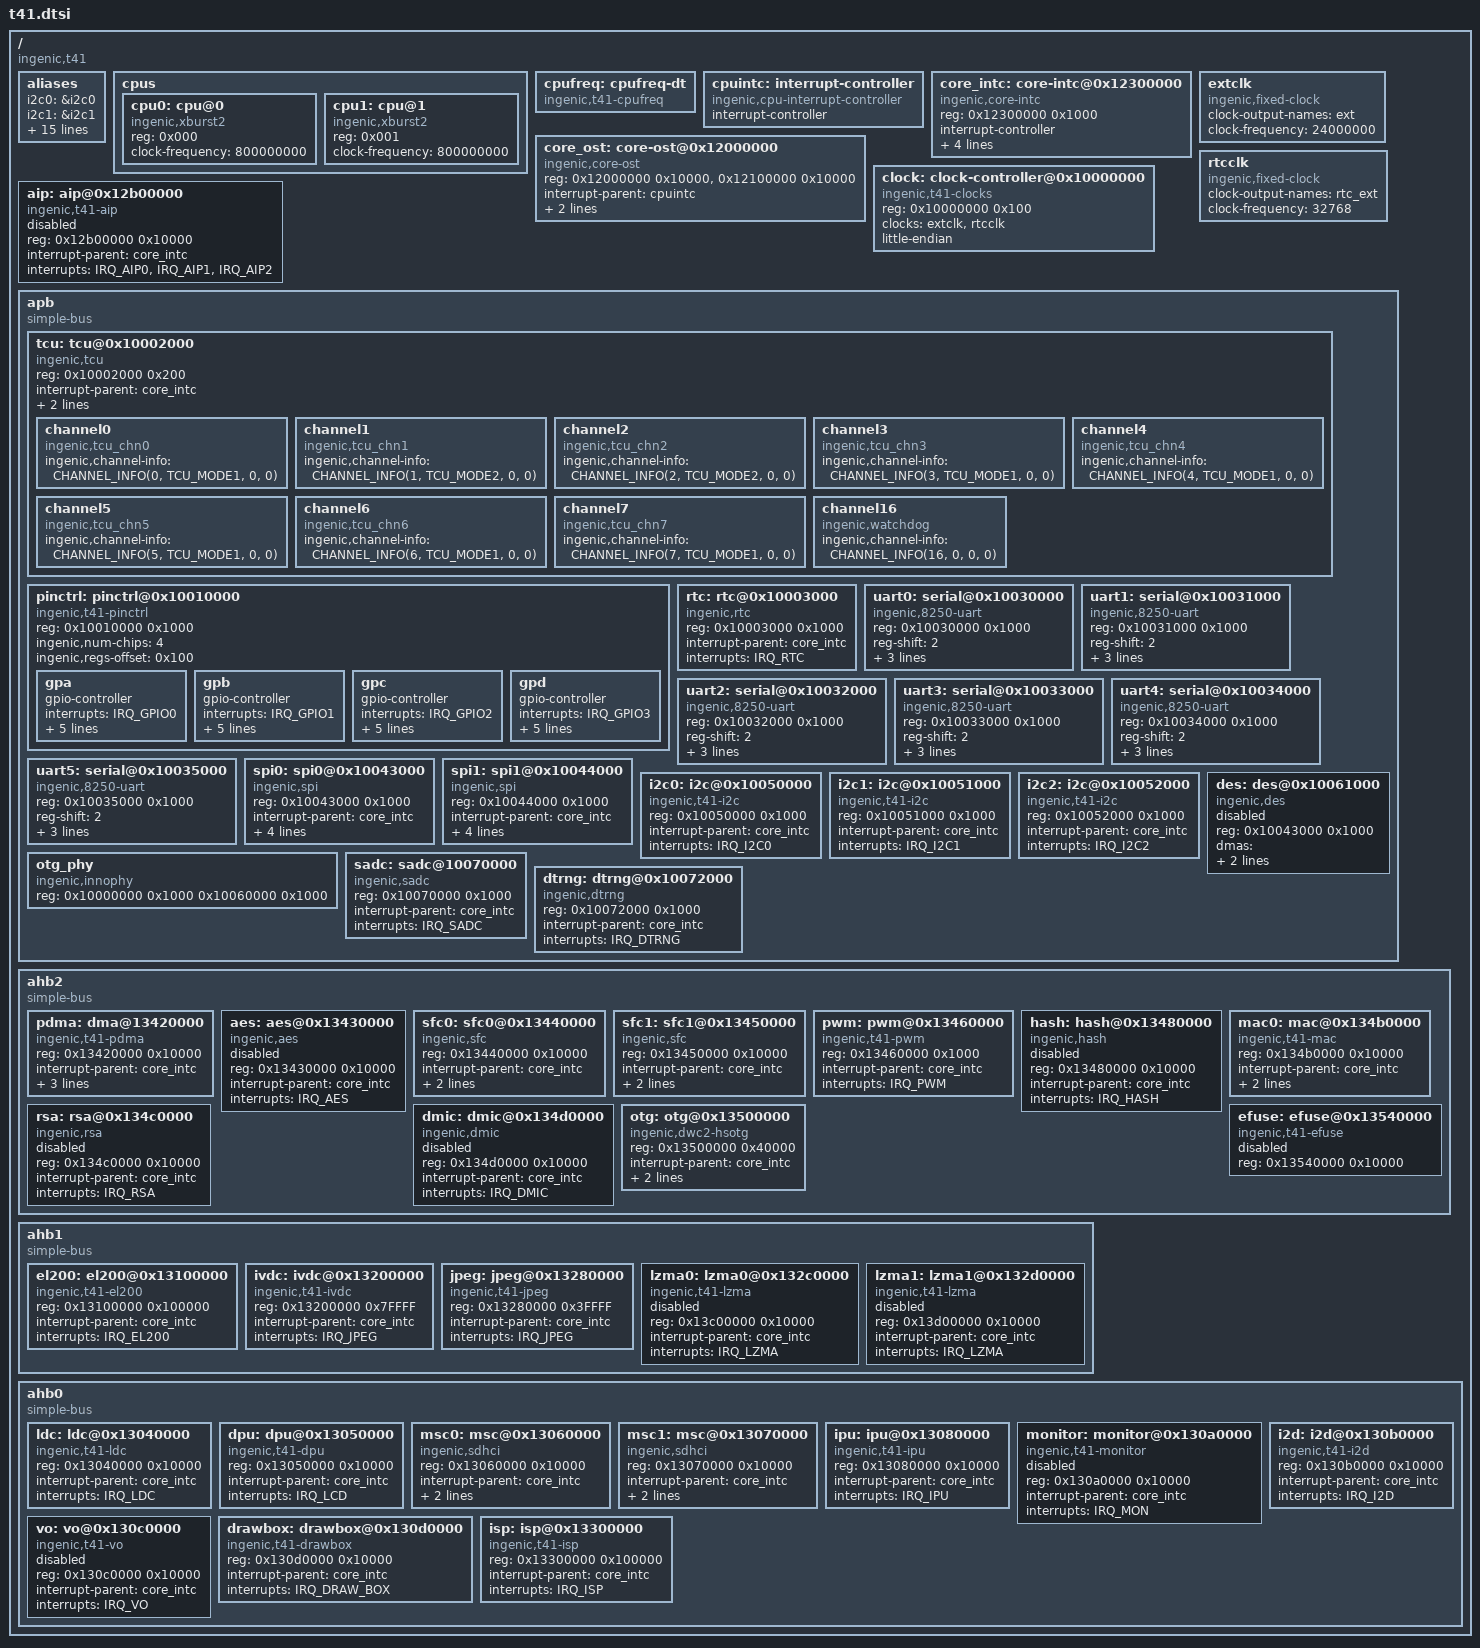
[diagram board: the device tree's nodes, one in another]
#include <dt-bindings/interrupt-controller/t41-irq.h>
#include <dt-bindings/clock/ingenic-tcu.h>
#include <dt-bindings/sound/ingenic-baic.h>
#include <dt-bindings/net/ingenic_gmac.h>
#include <dt-bindings/dma/ingenic-pdma.h>

/ {
	#address-cells = <1>;
	#size-cells = <1>;
	compatible = "ingenic,t41";

	aliases: aliases {
		i2c0 = &i2c0;
		i2c1 = &i2c1;
		i2c2 = &i2c2;
		vo   = &vo;
		uart0 = &uart0;
		uart1 = &uart1;
		uart2 = &uart2;
		uart3 = &uart3;
		uart4 = &uart4;
		uart5 = &uart5;
		msc0 = &msc0;
		msc1 = &msc1;
		mac0 = &mac0;
		spi0 = &spi0;
		spi1 = &spi1;
		sfc0 = &sfc0;
		sfc1 = &sfc1;
	};

	cpus: cpus {
		#address-cells = <1>;
		#size-cells = <0>;

		cpu0: cpu@0 {
			device_type = "cpu";
			compatible = "ingenic,xburst2";
			reg = <0x000>;
			clock-frequency = <800000000>;
		};

		cpu1: cpu@1 {
			device_type = "cpu";
			compatible = "ingenic,xburst2";
			reg = <0x001>;
			clock-frequency = <800000000>;
		};
	};

	cpufreq: cpufreq-dt {
		 compatible = "ingenic,t41-cpufreq";
		 status = "okay";
	};

	cpuintc: interrupt-controller {
		#address-cells = <0>;
		#interrupt-cells = <1>;
		interrupt-controller;
		compatible = "ingenic,cpu-interrupt-controller";

	};

	core_intc: core-intc@0x12300000 {
		compatible = "ingenic,core-intc";
		reg = <0x12300000 0x1000>;
		interrupt-controller;
		#interrupt-cells = <1>;
		cpu-intc-map = <0 0x000>,
				<1 0x100>,
				<2 0x200>,
				<3 0x300>;

		interrupt-parent = <&cpuintc>;
		interrupts = <CORE_INTC_IRQ>;
		interrupt-names ="intc";
	};

	core_ost: core-ost@0x12000000 {
		compatible = "ingenic,core-ost";
		reg = <0x12000000 0x10000>, /*Global ost*/
		      <0x12100000 0x10000>; /*Core ost*/
		interrupt-parent = <&cpuintc>;
		interrupt-names = "sys_ost";
		interrupts = <CORE_SYS_OST_IRQ>;
		cpu-ost-map = 	<0 0x000>,
			<1 0x100>;
	};

	extclk: extclk {
		compatible = "ingenic,fixed-clock";
		clock-output-names ="ext";
		#clock-cells = <0>;
		clock-frequency  = <24000000>;
	};

	rtcclk: rtcclk {
		compatible = "ingenic,fixed-clock";
		clock-output-names ="rtc_ext";
		#clock-cells = <0>;
		clock-frequency = <32768>;
	};

	clock: clock-controller@0x10000000 {
		compatible = "ingenic,t41-clocks";
		reg = <0x10000000 0x100>;
		clocks = <&extclk>, <&rtcclk>;
		clock-names = "ext", "rtc_ext";
		#clock-cells = <1>;
		little-endian;
	};

	aip: aip@0x12b00000 {
		compatible = "ingenic,t41-aip";
		reg = <0x12b00000 0x10000>;
		interrupt-parent = <&core_intc>;
		interrupts = <IRQ_AIP0>,
			<IRQ_AIP1>,
			<IRQ_AIP2>;
		status = "disabled";
	};

	apb {
		compatible = "simple-bus";
		#address-cells = <1>;
		#size-cells = <1>;
		ranges = <>;
		tcu: tcu@0x10002000 {
			compatible = "ingenic,tcu";
			reg = <0x10002000 0x200>;
			interrupt-parent = <&core_intc>;
			interrupt-names = "tcu_int0";
			interrupts = <IRQ_TCU0>;
			interrupt-controller;
			status = "okay";

			channel0: channel0 {
				compatible = "ingenic,tcu_chn0";
				ingenic,channel-info = <CHANNEL_INFO(0, TCU_MODE1, 0, 0)>;
			};
			channel1: channel1 {
				compatible = "ingenic,tcu_chn1";
				ingenic,channel-info = <CHANNEL_INFO(1, TCU_MODE2, 0, 0)>;
			};
			channel2: channel2 {
				compatible = "ingenic,tcu_chn2";
				ingenic,channel-info = <CHANNEL_INFO(2, TCU_MODE2, 0, 0)>;
			};
			channel3: channel3 {
				compatible = "ingenic,tcu_chn3";
				ingenic,channel-info = <CHANNEL_INFO(3, TCU_MODE1, 0, 0)>;
			};
			channel4: channel4 {
				compatible = "ingenic,tcu_chn4";
				ingenic,channel-info = <CHANNEL_INFO(4, TCU_MODE1, 0, 0)>;
			};
			channel5: channel5 {
				compatible = "ingenic,tcu_chn5";
				ingenic,channel-info = <CHANNEL_INFO(5, TCU_MODE1, 0, 0)>;
			};
			channel6: channel6 {
				compatible = "ingenic,tcu_chn6";
				ingenic,channel-info = <CHANNEL_INFO(6, TCU_MODE1, 0, 0)>;
			};
			channel7: channel7 {
				compatible = "ingenic,tcu_chn7";
				ingenic,channel-info = <CHANNEL_INFO(7, TCU_MODE1, 0, 0)>;
			};
			channel16: channel16 {
				compatible = "ingenic,watchdog";
				ingenic,channel-info = <CHANNEL_INFO(16, 0, 0, 0)>;
			};
		};

		pinctrl: pinctrl@0x10010000 {
			compatible = "ingenic,t41-pinctrl";
			reg = <0x10010000 0x1000>;
			ingenic,num-chips = <4>;
			ingenic,regs-offset = <0x100>;

			gpa: gpa {
				gpio-controller;
				#gpio-cells = <3>;
				#ingenic,pincfg-cells = <3>;
				#ingenic,pinmux-cells = <2>;
				interrupts = <IRQ_GPIO0>;
				interrupt-parent = <&core_intc>;
				interrupt-controller;
				#interrupt-cells = <3>;
				ingenic,num-gpios = <32>;
				ingenic,pull-gpios-low = <0x55555555>;
				ingenic,pull-gpios-high = <0x55555555>;
			};

			gpb: gpb {
				gpio-controller;
				#gpio-cells = <3>;
				#ingenic,pincfg-cells = <3>;
				#ingenic,pinmux-cells = <2>;
				interrupts = <IRQ_GPIO1>;
				interrupt-parent = <&core_intc>;
				interrupt-controller;
				#interrupt-cells = <3>;
				ingenic,num-gpios = <32>;
				ingenic,pull-gpios-low = <0x55555555>;
				ingenic,pull-gpios-high = <0x55555555>;
			};

			gpc: gpc {
				gpio-controller;
				#gpio-cells = <3>;
				#ingenic,pincfg-cells = <3>;
				#ingenic,pinmux-cells = <2>;
				interrupts = <IRQ_GPIO2>;
				interrupt-parent = <&core_intc>;
				interrupt-controller;
				#interrupt-cells = <3>;
				ingenic,num-gpios = <32>;
				ingenic,pull-gpios-low = <0x55555555>;
				ingenic,pull-gpios-high = <0x55555555>;
			};

			gpd: gpd {
				gpio-controller;
				#gpio-cells = <3>;
				#ingenic,pincfg-cells = <3>;
				#ingenic,pinmux-cells = <2>;
				interrupts = <IRQ_GPIO3>;
				interrupt-parent = <&core_intc>;
				interrupt-controller;
				#interrupt-cells = <3>;
				ingenic,num-gpios = <32>;
				ingenic,pull-gpios-low = <0x55555555>;
				ingenic,pull-gpios-high = <0x55555555>;
			};
		};

		rtc: rtc@0x10003000 {
			compatible = "ingenic,rtc";
			reg = <0x10003000 0x1000>;
			interrupt-parent = <&core_intc>;
			interrupts = <IRQ_RTC>;
			status = "okay";
		};

		uart0: serial@0x10030000 {
			compatible = "ingenic,8250-uart";
			reg = <0x10030000 0x1000>;
			reg-shift = <2>;
			interrupt-parent = <&core_intc>;
			interrupts = <IRQ_UART0>;
			pinctrl-names = "default";
			pinctrl-0 = <&uart0_pc>;
			status = "okay";
		};

		uart1: serial@0x10031000 {
			compatible = "ingenic,8250-uart";
			reg = <0x10031000 0x1000>;
			reg-shift = <2>;
			interrupt-parent = <&core_intc>;
			interrupts = <IRQ_UART1>;
			pinctrl-names = "default";
			pinctrl-0 = <&uart1_pb>;
			status = "okay";
		};

		uart2: serial@0x10032000 {
			compatible = "ingenic,8250-uart";
			reg = <0x10032000 0x1000>;
			reg-shift = <2>;
			interrupt-parent = <&core_intc>;
			interrupts = <IRQ_UART2>;
			pinctrl-names = "default";
			pinctrl-0 = <&uart2_pd>;
			status = "okay";
		};

		uart3: serial@0x10033000 {
			compatible = "ingenic,8250-uart";
			reg = <0x10033000 0x1000>;
			reg-shift = <2>;
			interrupt-parent = <&core_intc>;
			interrupts = <IRQ_UART3>;
			pinctrl-names = "default";
			pinctrl-0 = <&uart3_pd>;
			status = "okay";
		};

		uart4: serial@0x10034000 {
			compatible = "ingenic,8250-uart";
			reg = <0x10034000 0x1000>;
			reg-shift = <2>;
			interrupt-parent = <&core_intc>;
			interrupts = <IRQ_UART4>;
			pinctrl-names = "default";
			pinctrl-0 = <&uart4_pb>;
			status = "okay";
		};

		uart5: serial@0x10035000 {
			compatible = "ingenic,8250-uart";
			reg = <0x10035000 0x1000>;
			reg-shift = <2>;
			interrupt-parent = <&core_intc>;
			interrupts = <IRQ_UART5>;
			pinctrl-names = "default";
			pinctrl-0 = <&uart5_pd>;
			status = "okay";
		};

		spi0: spi0@0x10043000 {
			compatible = "ingenic,spi";
			reg = <0x10043000 0x1000>;
			interrupt-parent = <&core_intc>;
			interrupts = <IRQ_SSI0>;
			dmas = <&pdma INGENIC_DMA_TYPE(INGENIC_DMA_REQ_SSI0_TX)>,
				   <&pdma INGENIC_DMA_TYPE(INGENIC_DMA_REQ_SSI0_RX)>;
			dma-names = "tx", "rx";
			#address-cells = <1>;
			#size-cells = <0>;
			status = "okay";
		};

		spi1: spi1@0x10044000 {
			compatible = "ingenic,spi";
			reg = <0x10044000 0x1000>;
			interrupt-parent = <&core_intc>;
			interrupts = <IRQ_SSI1>;
			dmas = <&pdma INGENIC_DMA_TYPE(INGENIC_DMA_REQ_SSI1_TX)>,
				   <&pdma INGENIC_DMA_TYPE(INGENIC_DMA_REQ_SSI1_RX)>;
			dma-names = "tx", "rx";
			#address-cells = <1>;
			#size-cells = <0>;
			status = "okay";
		};

		i2c0: i2c@0x10050000 {
			compatible = "ingenic,t41-i2c";
			reg = <0x10050000 0x1000>;
			interrupt-parent = <&core_intc>;
			interrupts = <IRQ_I2C0>;
			#address-cells = <1>;
			#size-cells = <0>;
			status = "okay";
		};

		i2c1: i2c@0x10051000 {
			compatible = "ingenic,t41-i2c";
			reg = <0x10051000 0x1000>;
			interrupt-parent = <&core_intc>;
			interrupts = <IRQ_I2C1>;
			#address-cells = <1>;
			#size-cells = <0>;
			status = "okay";
		};

		i2c2: i2c@0x10052000 {
			compatible = "ingenic,t41-i2c";
			reg = <0x10052000 0x1000>;
			interrupt-parent = <&core_intc>;
			interrupts = <IRQ_I2C2>;
			#address-cells = <1>;
			#size-cells = <0>;
			status = "okay";
		};

		otg_phy: otg_phy {
			compatible = "ingenic,innophy";
			reg = <0x10000000 0x1000 0x10060000 0x1000>;
		};

		des: des@0x10061000 {
			compatible = "ingenic,des";
			reg = <0x10043000 0x1000>;
			dmas = <&pdma INGENIC_DMA_TYPE(INGENIC_DMA_REQ_DES_TX)>,
			<&pdma INGENIC_DMA_TYPE(INGENIC_DMA_REQ_DES_RX)>;
			dma-names = "tx", "rx";
			#address-cells = <1>;
			#size-cells = <0>;
			status = "disabled";
		};

		sadc: sadc@10070000 {
			compatible = "ingenic,sadc";
			reg = <0x10070000 0x1000>;
			interrupt-parent = <&core_intc>;
			interrupts = <IRQ_SADC>;
			status = "okay";
		};

		dtrng: dtrng@0x10072000 {
			compatible = "ingenic,dtrng";
			reg = <0x10072000 0x1000>;
			interrupt-parent = <&core_intc>;
			interrupts = <IRQ_DTRNG>;
			status = "okay";
		};
	};

	ahb2 {
		compatible = "simple-bus";
		#address-cells = <1>;
		#size-cells = <1>;
		ranges = <>;

		pdma: dma@13420000 {
			compatible = "ingenic,t41-pdma";
			reg = <0x13420000 0x10000>;
			interrupt-parent = <&core_intc>;
			interrupt-names = "pdma", "pdmam";
			interrupts = <IRQ_PDMA>, <IRQ_PDMAM>;
			#dma-channels = <32>;
			#dma-cells = <1>;
			ingenic,reserved-chs = <0x3>;
		};

		aes: aes@0x13430000 {
			compatible = "ingenic,aes";
			reg = <0x13430000 0x10000>;
			interrupt-parent = <&core_intc>;
			interrupts = <IRQ_AES>;
			status = "disabled";
		};

		sfc0: sfc0@0x13440000 {
			compatible = "ingenic,sfc";
			reg = <0x13440000 0x10000>;
			interrupt-parent = <&core_intc>;
			interrupts = <IRQ_SFC0>;
			pinctrl-names = "default";
			pinctrl-0 = <&sfc0_pa>;
			status = "okay";
		};

		sfc1: sfc1@0x13450000 {
			compatible = "ingenic,sfc";
			reg = <0x13450000 0x10000>;
			interrupt-parent = <&core_intc>;
			interrupts = <IRQ_SFC1>;
			pinctrl-names = "default";
			pinctrl-0 = <&sfc1_pa>;
			status = "okay";
		};

		pwm: pwm@0x13460000 {
			compatible = "ingenic,t41-pwm";
			reg = <0x13460000 0x1000>;
			interrupt-parent = <&core_intc>;
			interrupts = <IRQ_PWM>;
			#address-cells = <1>;
			#size-cells = <0>;
			status = "okay";
		};

		hash: hash@0x13480000 {
			compatible = "ingenic,hash";
			reg = <0x13480000 0x10000>;
			interrupt-parent = <&core_intc>;
			interrupts = <IRQ_HASH>;
			status = "disabled";
		};

		mac0: mac@0x134b0000 {
			compatible = "ingenic,t41-mac";
			reg = <0x134b0000 0x10000>;
			interrupt-parent = <&core_intc>;
			interrupts = <IRQ_GMAC0>;
			status = "okay";
			ingenic,rst-ms = <10>;
		};

		rsa: rsa@0x134c0000 {
			compatible = "ingenic,rsa";
			reg = <0x134c0000 0x10000>;
			interrupt-parent = <&core_intc>;
			interrupts = <IRQ_RSA>;
			status = "disabled";
		};

		dmic: dmic@0x134d0000 {
			compatible = "ingenic,dmic";
			reg = <0x134d0000 0x10000>;
			interrupt-parent = <&core_intc>;
			interrupts = <IRQ_DMIC>;
			status = "disabled";
		};

		otg: otg@0x13500000 {
			compatible = "ingenic,dwc2-hsotg";
			reg = <0x13500000 0x40000>;
			interrupt-parent = <&core_intc>;
			interrupts = <IRQ_OTG>;
			ingenic,usbphy=<&otg_phy>;
			status = "okay";
		};

		efuse: efuse@0x13540000 {
			compatible = "ingenic,t41-efuse";
			reg = <0x13540000 0x10000>;
			status = "disabled";
		};
	};

	ahb1 {
		compatible = "simple-bus";
		#address-cells = <1>;
		#size-cells = <1>;
		ranges = <>;

		el200: el200@0x13100000 {
			compatible = "ingenic,t41-el200";
			reg = <0x13100000 0x100000>;
			interrupt-parent = <&core_intc>;
			interrupts = <IRQ_EL200>;
			status = "okay";
		};

		ivdc: ivdc@0x13200000 {
			compatible = "ingenic,t41-ivdc";
			reg = <0x13200000 0x7FFFF>;
			interrupt-parent = <&core_intc>;
			interrupts = <IRQ_JPEG>;
			status = "okay";
		};

		jpeg: jpeg@0x13280000 {
			compatible = "ingenic,t41-jpeg";
			reg = <0x13280000 0x3FFFF>;
			interrupt-parent = <&core_intc>;
			interrupts = <IRQ_JPEG>;
			status = "okay";
		};

		lzma0: lzma0@0x132c0000 {
			compatible = "ingenic,t41-lzma";
			reg = <0x13c00000 0x10000>;
			interrupt-parent = <&core_intc>;
			interrupts = <IRQ_LZMA>;
			status = "disabled";
		};

		lzma1: lzma1@0x132d0000 {
			compatible = "ingenic,t41-lzma";
			reg = <0x13d00000 0x10000>;
			interrupt-parent = <&core_intc>;
			interrupts = <IRQ_LZMA>;
			status = "disabled";
		};
	};

	ahb0 {
		compatible = "simple-bus";
		#address-cells = <1>;
		#size-cells = <1>;
		ranges = <>;

		ldc: ldc@0x13040000 {
			compatible = "ingenic,t41-ldc";
			reg = <0x13040000 0x10000>;
			interrupt-parent = <&core_intc>;
			interrupts = <IRQ_LDC>;
			status = "okay";
		};

		dpu: dpu@0x13050000 {
			compatible = "ingenic,t41-dpu";
			reg = <0x13050000 0x10000>;
			interrupt-parent = <&core_intc>;
			interrupts = <IRQ_LCD>;
			status = "okay";
		};
		msc0: msc@0x13060000 {
			compatible = "ingenic,sdhci";
			reg = <0x13060000 0x10000>;
			status = "okay";
			interrupt-parent = <&core_intc>;
			interrupts = <IRQ_MSC0>;
			pinctrl-names ="default";
			pinctrl-0 = <&msc0_4bit>;
		};

		msc1: msc@0x13070000 {
			compatible = "ingenic,sdhci";
			reg = <0x13070000 0x10000>;
			status = "okay";
			interrupt-parent = <&core_intc>;
			interrupts = <IRQ_MSC1>;
			pinctrl-names ="default";
			pinctrl-0 = <&msc1_4bit>;
		};

		ipu: ipu@0x13080000 {
			compatible = "ingenic,t41-ipu";
			reg = <0x13080000 0x10000>;
			interrupt-parent = <&core_intc>;
			interrupts = <IRQ_IPU>;
			status = "okay";
		};

		monitor: monitor@0x130a0000 {
			compatible = "ingenic,t41-monitor";
			reg = <0x130a0000 0x10000>;
			interrupt-parent = <&core_intc>;
			interrupts = <IRQ_MON>;
			status = "disabled";
		};

		i2d: i2d@0x130b0000 {
			compatible = "ingenic,t41-i2d";
			reg = <0x130b0000 0x10000>;
			interrupt-parent = <&core_intc>;
			interrupts = <IRQ_I2D>;
			status = "okay";
        };

		vo: vo@0x130c0000 {
			compatible = "ingenic,t41-vo";
			reg = <0x130c0000 0x10000>;
			interrupt-parent = <&core_intc>;
			interrupts = <IRQ_VO>;
			status = "disabled";
		};

		drawbox: drawbox@0x130d0000 {
			 compatible = "ingenic,t41-drawbox";
			 reg = <0x130d0000 0x10000>;
			 interrupt-parent = <&core_intc>;
			 interrupts = <IRQ_DRAW_BOX>;
			 status = "okay";
		};

		isp: isp@0x13300000 {
			compatible = "ingenic,t41-isp";
			reg = <0x13300000 0x100000>;
			interrupt-parent = <&core_intc>;
			interrupts = <IRQ_ISP>;
			status = "okay";
		};
	};
};
#include "t41-pinctrl.dtsi"
